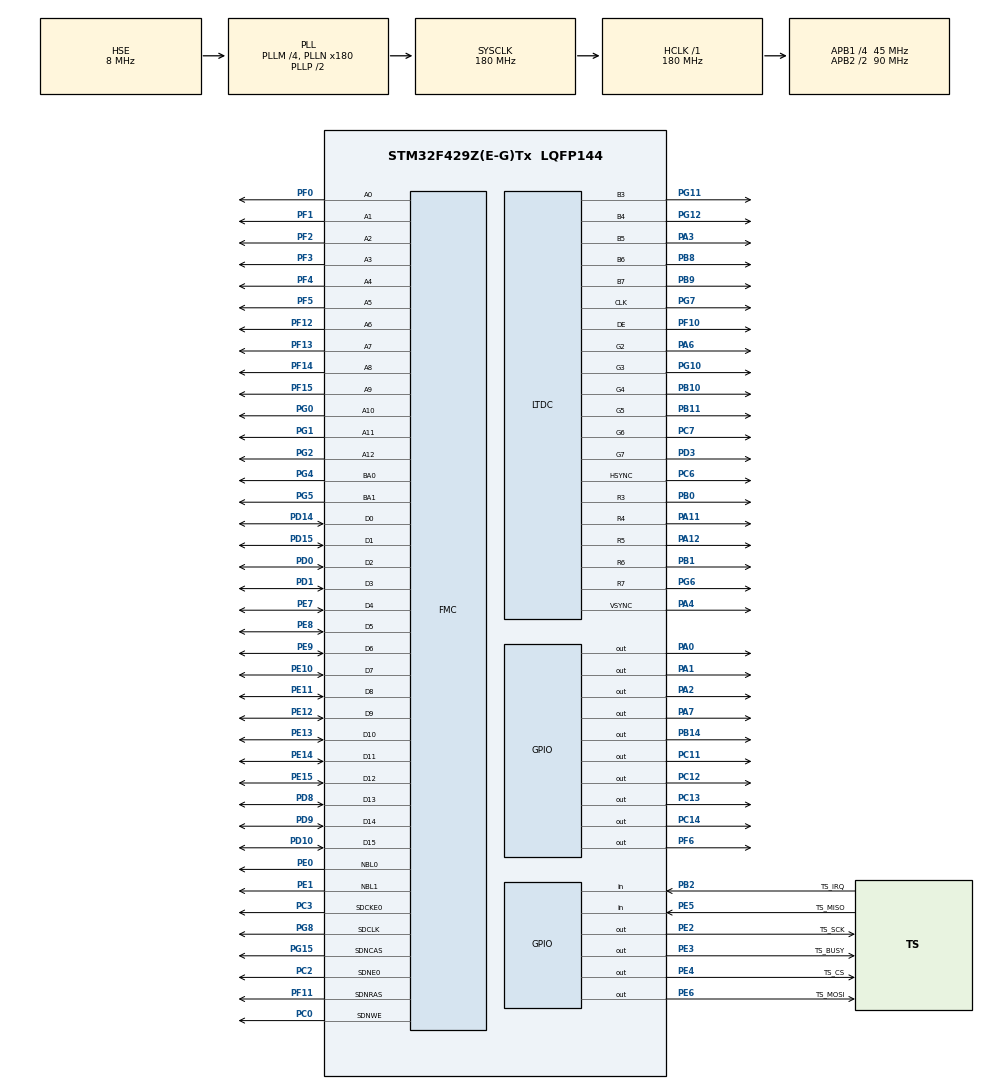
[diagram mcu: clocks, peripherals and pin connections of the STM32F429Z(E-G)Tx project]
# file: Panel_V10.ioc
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DMA2D.ColorMode=DMA2D_OUTPUT_RGB565
FMC.CASLatency1=FMC_SDRAM_CAS_LATENCY_2
FMC.ColumnBitsNumber1=FMC_SDRAM_COLUMN_BITS_NUM_9
FMC.ExitSelfRefreshDelay1=7
FMC.LoadToActiveDelay1=2
FMC.RCDDelay1=2
FMC.RPDelay1=2
FMC.RPDelay2=2
FMC.RowCycleDelay1=7
FMC.RowCycleDelay2=7
FMC.SDClockPeriod1=FMC_SDRAM_CLOCK_PERIOD_2
FMC.SDClockPeriod2=FMC_SDRAM_CLOCK_PERIOD_2
FMC.SelfRefreshTime1=4
FMC.WriteRecoveryTime1=3
FREERTOS.Tasks01=defaultTask,0,2048,StartDefaultTask,Default,NULL,Dynamic,NULL,NULL
FREERTOS.configMINIMAL_STACK_SIZE=2048
LTDC.ActiveH=272
LTDC.ActiveW=480
LTDC.Alpha_L0=255
LTDC.FBStartAdress_L0=0xC0000000
LTDC.HBP=43
LTDC.HFP=2
LTDC.HSync=1
LTDC.ImageHeight_L0=272
LTDC.ImageWidth_L0=480
LTDC.Layers=0
LTDC.PixelFormat_L0=LTDC_PIXEL_FORMAT_RGB565
LTDC.VBP=12
LTDC.VFP=2
LTDC.VSync=1
LTDC.WindowX1_L0=480
LTDC.WindowY1_L0=272
Mcu.Family=STM32F4
Mcu.Name=STM32F429Z(E-G)Tx
Mcu.Package=LQFP144
NVIC.DMA2D_IRQn=true\:5\:0\:false\:false\:true\:true\:true\:true
NVIC.LTDC_IRQn=true\:5\:0\:false\:false\:true\:true\:true\:true
NVIC.PriorityGroup=NVIC_PRIORITYGROUP_4
NVIC.RCC_IRQn=true\:5\:0\:false\:false\:true\:true\:false\:false
NVIC.TIM1_UP_TIM10_IRQn=true\:0\:0\:false\:false\:true\:false\:true\:true
NVIC.TimeBase=TIM1_UP_TIM10_IRQn
NVIC.TimeBaseIP=TIM1
PA0/WKUP.Signal=GPIO_Output
PA1.Signal=GPIO_Output
PA11.GPIO_Speed=GPIO_SPEED_FREQ_VERY_HIGH
PA11.Mode=RGB565
PA11.Signal=LTDC_R4
PA12.GPIO_Speed=GPIO_SPEED_FREQ_VERY_HIGH
PA12.Mode=RGB565
PA12.Signal=LTDC_R5
PA13.Mode=Serial_Wire
PA13.Signal=SYS_JTMS-SWDIO
PA14.Mode=Serial_Wire
PA14.Signal=SYS_JTCK-SWCLK
PA2.Signal=GPIO_Output
PA3.GPIO_Speed=GPIO_SPEED_FREQ_VERY_HIGH
PA3.Mode=RGB565
PA3.Signal=LTDC_B5
PA4.GPIO_Speed=GPIO_SPEED_FREQ_VERY_HIGH
PA4.Mode=RGB565
PA4.Signal=LTDC_VSYNC
PA6.GPIO_Speed=GPIO_SPEED_FREQ_VERY_HIGH
PA6.Mode=RGB565
PA6.Signal=LTDC_G2
PA7.Signal=GPIO_Output
PB0.GPIO_Speed=GPIO_SPEED_FREQ_VERY_HIGH
PB0.Mode=RGB565
PB0.Signal=LTDC_R3
PB1.GPIO_Speed=GPIO_SPEED_FREQ_VERY_HIGH
PB1.Mode=RGB565
PB1.Signal=LTDC_R6
PB10.GPIO_Speed=GPIO_SPEED_FREQ_VERY_HIGH
PB10.Mode=RGB565
PB10.Signal=LTDC_G4
PB11.GPIO_Speed=GPIO_SPEED_FREQ_VERY_HIGH
PB11.Mode=RGB565
PB11.Signal=LTDC_G5
PB14.PinState=GPIO_PIN_SET
PB14.Signal=GPIO_Output
PB2/BOOT1.GPIO_Label=TS_IRQ
PB2/BOOT1.Signal=GPIO_Input
PB8.GPIO_Speed=GPIO_SPEED_FREQ_VERY_HIGH
PB8.Mode=RGB565
PB8.Signal=LTDC_B6
PB9.GPIO_Speed=GPIO_SPEED_FREQ_VERY_HIGH
PB9.Mode=RGB565
PB9.Signal=LTDC_B7
PC0.Signal=FMC_SDNWE
PC11.Signal=GPIO_Output
PC12.Signal=GPIO_Output
PC13.Signal=GPIO_Output
PC14/OSC32_IN.Signal=GPIO_Output
PC2.Mode=SdramChipSelect1_1
PC2.Signal=FMC_SDNE0
PC3.Mode=SdramChipSelect1_1
PC3.Signal=FMC_SDCKE0
PC6.GPIO_Speed=GPIO_SPEED_FREQ_VERY_HIGH
PC6.Mode=RGB565
PC6.Signal=LTDC_HSYNC
PC7.GPIO_Speed=GPIO_SPEED_FREQ_VERY_HIGH
PC7.Mode=RGB565
PC7.Signal=LTDC_G6
PD0.Signal=FMC_D2_DA2
PD1.Signal=FMC_D3_DA3
PD10.Signal=FMC_D15_DA15
PD14.Signal=FMC_D0_DA0
PD15.Signal=FMC_D1_DA1
PD3.GPIO_Speed=GPIO_SPEED_FREQ_VERY_HIGH
PD3.Mode=RGB565
PD3.Signal=LTDC_G7
PD8.Signal=FMC_D13_DA13
PD9.Signal=FMC_D14_DA14
PE0.Signal=FMC_NBL0
PE1.Signal=FMC_NBL1
PE10.Signal=FMC_D7_DA7
PE11.Signal=FMC_D8_DA8
PE12.Signal=FMC_D9_DA9
PE13.Signal=FMC_D10_DA10
PE14.Signal=FMC_D11_DA11
PE15.Signal=FMC_D12_DA12
PE2.GPIO_Label=TS_SCK
PE2.Signal=GPIO_Output
PE3.GPIO_Label=TS_BUSY
PE3.Signal=GPIO_Output
PE4.GPIO_Label=TS_CS
PE4.Signal=GPIO_Output
PE5.GPIO_Label=TS_MISO
PE5.Signal=GPIO_Input
PE6.GPIO_Label=TS_MOSI
PE6.Signal=GPIO_Output
PE7.Signal=FMC_D4_DA4
PE8.Signal=FMC_D5_DA5
PE9.Signal=FMC_D6_DA6
PF0.Signal=FMC_A0
PF1.Signal=FMC_A1
PF10.GPIO_Speed=GPIO_SPEED_FREQ_VERY_HIGH
PF10.Mode=RGB565
PF10.Signal=LTDC_DE
PF11.Signal=FMC_SDNRAS
PF12.Signal=FMC_A6
PF13.Signal=FMC_A7
PF14.Signal=FMC_A8
PF15.Signal=FMC_A9
PF2.Signal=FMC_A2
PF3.Signal=FMC_A3
PF4.Signal=FMC_A4
PF5.Signal=FMC_A5
PF6.PinState=GPIO_PIN_SET
PF6.Signal=GPIO_Output
PG0.Signal=FMC_A10
PG1.Signal=FMC_A11
PG10.GPIO_Speed=GPIO_SPEED_FREQ_VERY_HIGH
PG10.Mode=RGB565
PG10.Signal=LTDC_G3
PG11.GPIO_Speed=GPIO_SPEED_FREQ_VERY_HIGH
PG11.Mode=RGB565
PG11.Signal=LTDC_B3
PG12.GPIO_Speed=GPIO_SPEED_FREQ_VERY_HIGH
PG12.Mode=RGB565
PG12.Signal=LTDC_B4
PG15.Signal=FMC_SDNCAS
PG2.Signal=FMC_A12
PG4.Signal=FMC_A14_BA0
PG5.Signal=FMC_A15_BA1
PG6.GPIO_Speed=GPIO_SPEED_FREQ_VERY_HIGH
PG6.Mode=RGB565
PG6.Signal=LTDC_R7
PG7.GPIO_Speed=GPIO_SPEED_FREQ_VERY_HIGH
PG7.Mode=RGB565
PG7.Signal=LTDC_CLK
PG8.Signal=FMC_SDCLK
PH0/OSC_IN.Mode=HSE-External-Oscillator
PH0/OSC_IN.Signal=RCC_OSC_IN
PH1/OSC_OUT.Mode=HSE-External-Oscillator
PH1/OSC_OUT.Signal=RCC_OSC_OUT
ProjectManager.HeapSize=0x200
ProjectManager.StackSize=0x400
ProjectManager.TargetToolchain=STM32CubeIDE
RCC.48MHZClocksFreq_Value=90000000
RCC.AHBFreq_Value=180000000
RCC.APB1CLKDivider=RCC_HCLK_DIV4
RCC.APB1Freq_Value=45000000
RCC.APB1TimFreq_Value=90000000
RCC.APB2CLKDivider=RCC_HCLK_DIV2
RCC.APB2Freq_Value=90000000
RCC.APB2TimFreq_Value=180000000
RCC.CortexFreq_Value=180000000
RCC.HCLKFreq_Value=180000000
RCC.HSE_VALUE=8000000
RCC.HSI_VALUE=16000000
RCC.LSE_VALUE=32768
RCC.PLLM=4
RCC.PLLN=180
RCC.PLLSAIDivR=RCC_PLLSAIDIVR_4
RCC.PLLSAIN=54
RCC.PLLSAIR=3
RCC.PLLSourceVirtual=RCC_PLLSOURCE_HSE
RCC.PWR_Regulator_Voltage_Scale=PWR_REGULATOR_VOLTAGE_SCALE1
RCC.SYSCLKFreq_VALUE=180000000
RCC.SYSCLKSource=RCC_SYSCLKSOURCE_PLLCLK
RCC.VCOOutputFreq_Value=360000000
SH.FMC_A0.0=FMC_A0,13b-sda1
SH.FMC_A1.0=FMC_A1,13b-sda1
SH.FMC_A10.0=FMC_A10,13b-sda1
SH.FMC_A11.0=FMC_A11,13b-sda1
SH.FMC_A12.0=FMC_A12,13b-sda1
SH.FMC_A14_BA0.0=FMC_BA0,FourSdramBanks1
SH.FMC_A15_BA1.0=FMC_BA1,FourSdramBanks1
SH.FMC_A2.0=FMC_A2,13b-sda1
SH.FMC_A3.0=FMC_A3,13b-sda1
SH.FMC_A4.0=FMC_A4,13b-sda1
SH.FMC_A5.0=FMC_A5,13b-sda1
SH.FMC_A6.0=FMC_A6,13b-sda1
SH.FMC_A7.0=FMC_A7,13b-sda1
SH.FMC_A8.0=FMC_A8,13b-sda1
SH.FMC_A9.0=FMC_A9,13b-sda1
SH.FMC_D0_DA0.0=FMC_D0,sd-16b-d1
SH.FMC_D10_DA10.0=FMC_D10,sd-16b-d1
SH.FMC_D11_DA11.0=FMC_D11,sd-16b-d1
SH.FMC_D12_DA12.0=FMC_D12,sd-16b-d1
SH.FMC_D13_DA13.0=FMC_D13,sd-16b-d1
SH.FMC_D14_DA14.0=FMC_D14,sd-16b-d1
SH.FMC_D15_DA15.0=FMC_D15,sd-16b-d1
SH.FMC_D1_DA1.0=FMC_D1,sd-16b-d1
SH.FMC_D2_DA2.0=FMC_D2,sd-16b-d1
SH.FMC_D3_DA3.0=FMC_D3,sd-16b-d1
SH.FMC_D4_DA4.0=FMC_D4,sd-16b-d1
SH.FMC_D5_DA5.0=FMC_D5,sd-16b-d1
SH.FMC_D6_DA6.0=FMC_D6,sd-16b-d1
SH.FMC_D7_DA7.0=FMC_D7,sd-16b-d1
SH.FMC_D8_DA8.0=FMC_D8,sd-16b-d1
SH.FMC_D9_DA9.0=FMC_D9,sd-16b-d1
SH.FMC_NBL0.0=FMC_NBL0,Sd2ByteEnable1
SH.FMC_NBL1.0=FMC_NBL1,Sd2ByteEnable1
SH.FMC_SDCLK.0=FMC_SDCLK,13b-sda1
SH.FMC_SDNCAS.0=FMC_SDNCAS,13b-sda1
SH.FMC_SDNRAS.0=FMC_SDNRAS,13b-sda1
SH.FMC_SDNWE.0=FMC_SDNWE,13b-sda1
STMicroelectronics.X-CUBE-TOUCHGFX.4.16.1.ApplicationCcGraphicsJjApplication=TouchGFXOoGenerator
STMicroelectronics.X-CUBE-TOUCHGFX.4.16.1.tgfx_address1=0xC0000000
STMicroelectronics.X-CUBE-TOUCHGFX.4.16.1.tgfx_display_interface=disp_ltdc
STMicroelectronics.X-CUBE-TOUCHGFX.4.16.1.tgfx_hardware_accelerator=dma_2d
STMicroelectronics.X-CUBE-TOUCHGFX.4.16.1.tgfx_location=By Address
STMicroelectronics.X-CUBE-TOUCHGFX.4.16.1.tgfx_vsync=vsync_ltdc
VP_CRC_VS_CRC.Mode=CRC_Activate
VP_DMA2D_VS_DMA2D.Mode=DMA2D_Activate
VP_FREERTOS_VS_CMSIS_V1.Mode=CMSIS_V1
VP_STMicroelectronics.X-CUBE-TOUCHGFX_VS_GraphicsJjApplication_4.16.1.Mode=GraphicsJjApplication
VP_SYS_VS_tim1.Mode=TIM1
board=custom

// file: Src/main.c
/* USER CODE BEGIN Header */
/**
  ******************************************************************************
  * @file           : main.c
  * @brief          : Main program body
  ******************************************************************************
  * @attention
  *
  * <h2><center>&copy; Copyright (c) 2020 STMicroelectronics.
  * All rights reserved.</center></h2>
  *
  * This software component is licensed by ST under BSD 3-Clause license,
  * the "License"; You may not use this file except in compliance with the
  * License. You may obtain a copy of the License at:
  *                        opensource.org/licenses/BSD-3-Clause
  *
  ******************************************************************************
  */
/* USER CODE END Header */
#include "main.h"
#include "cmsis_os.h"
#include "app_touchgfx.h"

/* USER CODE BEGIN Includes */
int tickcounter;
int q;
int tick;
int m;

/* USER CODE END Includes */

/* USER CODE BEGIN PM */
# define WRITE_READ_ADDR                                ((uint16_t*)0xC0000000)

# define SDRAM_MODEREG_BURST_LENGTH_1                   ((uint16_t)0x0000)
# define SDRAM_MODEREG_BURST_LENGTH_2                   ((uint16_t)0x0001)
# define SDRAM_MODEREG_BURST_LENGTH_4                   ((uint16_t)0x0002)
# define SDRAM_MODEREG_BURST_LENGTH_8                   ((uint16_t)0x0004)
# define SDRAM_MODEREG_BURST_TYPE_SEQUENTIAL            ((uint16_t)0x0000)
# define SDRAM_MODEREG_BURST_TYPE_INTERLEAVED           ((uint16_t)0x0008)
# define SDRAM_MODEREG_CAS_LATENCY_2                    ((uint16_t)0x0020)
# define SDRAM_MODEREG_CAS_LATENCY_3                    ((uint16_t)0x0030)
# define SDRAM_MODEREG_OPERATING_MODE_STANDARD          ((uint16_t)0x0000)
# define SDRAM_MODEREG_WRITEBURST_MODE_PROGRAMMED       ((uint16_t)0x0000)
# define SDRAM_MODEREG_WRITEBURST_MODE_SINGLE           ((uint16_t)0x0200)

# define REFRESH_COUNT                                  ((uint32_t)1835)        // SDRAM Refresh Counter (90MHz SD Clock)

void SDRAM_Initialization_Sequence(SDRAM_HandleTypeDef *hsdram, FMC_SDRAM_CommandTypeDef *Command)
{
  __IO uint32_t tmpmrd = 0;

  // Step 3: Configure a clock configuration enable command
  Command->CommandMode                  =       FMC_SDRAM_CMD_CLK_ENABLE;
  Command->CommandTarget                =       FMC_SDRAM_CMD_TARGET_BANK1;
  Command->AutoRefreshNumber            =       1;
  Command->ModeRegisterDefinition       =       0;

  // Send the command
  HAL_SDRAM_SendCommand(hsdram, Command, 0x1000);

  // Step 4: Insert 100 ms delay
  HAL_Delay(100);

  // Step 5: Configure a PALL (Precharge All) command
  Command->CommandMode                  =       FMC_SDRAM_CMD_PALL;
  Command->CommandTarget                =       FMC_SDRAM_CMD_TARGET_BANK1;
  Command->AutoRefreshNumber            =       1;
  Command->ModeRegisterDefinition       =       0;

  // Send the command
  HAL_SDRAM_SendCommand(hsdram, Command, 0x1000);

  // Step 6: Configure a Auto-Refresh command
  Command->CommandMode                  =       FMC_SDRAM_CMD_AUTOREFRESH_MODE;
  Command->CommandTarget                =       FMC_SDRAM_CMD_TARGET_BANK1;
  Command->AutoRefreshNumber            =       8;
  Command->ModeRegisterDefinition       =       0;

  // Send the command
  HAL_SDRAM_SendCommand(hsdram, Command, 0x1000);

  // Step 7: Program the external memory mode register
  tmpmrd = (uint32_t) SDRAM_MODEREG_BURST_LENGTH_2              |
                      SDRAM_MODEREG_BURST_TYPE_SEQUENTIAL       |
                      SDRAM_MODEREG_CAS_LATENCY_3               |
                      SDRAM_MODEREG_OPERATING_MODE_STANDARD     |
                      SDRAM_MODEREG_WRITEBURST_MODE_SINGLE      ;

  Command->CommandMode                  =       FMC_SDRAM_CMD_LOAD_MODE;
  Command->CommandTarget                =       FMC_SDRAM_CMD_TARGET_BANK1;
  Command->AutoRefreshNumber            =       1;
  Command->ModeRegisterDefinition       =       0x0220;

  // Send the command
  HAL_SDRAM_SendCommand(hsdram, Command, 0x1000);

  // Step 8: Set the refresh rate counter -----> (15.62 us * Freq) - 20
  // Set the device refresh counter
  HAL_SDRAM_ProgramRefreshRate(hsdram, REFRESH_COUNT);
}

/* USER CODE END PM */

CRC_HandleTypeDef hcrc;

DMA2D_HandleTypeDef hdma2d;

LTDC_HandleTypeDef hltdc;

SDRAM_HandleTypeDef hsdram1;

osThreadId defaultTaskHandle;

void SystemClock_Config(void);
static void MX_GPIO_Init(void);
static void MX_CRC_Init(void);
static void MX_FMC_Init(void);
static void MX_LTDC_Init(void);
static void MX_DMA2D_Init(void);
void StartDefaultTask(void const * argument);

/* USER CODE BEGIN PFP */
void StartTask1(void const * argument);
void StartTask2(void const * argument);

/* USER CODE END PFP */

int main(void)
{

  /* MCU Configuration--------------------------------------------------------*/

  /* Reset of all peripherals, Initializes the Flash interface and the Systick. */
  HAL_Init();

  /* Configure the system clock */
  SystemClock_Config();

  /* Initialize all configured peripherals */
  MX_GPIO_Init();
  MX_CRC_Init();
  MX_FMC_Init();
  MX_LTDC_Init();
  MX_DMA2D_Init();
  MX_TouchGFX_Init();
  /* USER CODE BEGIN 2 */
  HAL_GPIO_WritePin(GPIOA, GPIO_PIN_0, GPIO_PIN_SET);
  HAL_GPIO_WritePin(GPIOA, GPIO_PIN_1, GPIO_PIN_SET);
  HAL_GPIO_WritePin(GPIOA, GPIO_PIN_2, GPIO_PIN_SET);
  HAL_GPIO_WritePin(GPIOA, GPIO_PIN_7, GPIO_PIN_SET);
  HAL_GPIO_WritePin(GPIOC, GPIO_PIN_11, GPIO_PIN_SET);
  HAL_GPIO_WritePin(GPIOC, GPIO_PIN_12, GPIO_PIN_SET);
  HAL_GPIO_WritePin(GPIOC, GPIO_PIN_13, GPIO_PIN_SET);
  HAL_GPIO_WritePin(GPIOC, GPIO_PIN_14, GPIO_PIN_SET);
  /* USER CODE END 2 */

  /* Create the thread(s) */
  /* definition and creation of defaultTask */
  osThreadDef(defaultTask, StartDefaultTask, osPriorityNormal, 0, 2048);
  defaultTaskHandle = osThreadCreate(osThread(defaultTask), NULL);

  /* USER CODE BEGIN RTOS_THREADS */
  /* add threads, ... */
  osThreadDef(Task1, StartTask1, osPriorityNormal, 0, 128);
  defaultTaskHandle = osThreadCreate(osThread(Task1), NULL);

  osThreadDef(Task2, StartTask2, osPriorityNormal, 0, 128);
  defaultTaskHandle = osThreadCreate(osThread(Task2), NULL);

  /* USER CODE END RTOS_THREADS */

  /* Start scheduler */
  osKernelStart();

  /* We should never get here as control is now taken by the scheduler */
  /* Infinite loop */
  while (1)
  {

  }
}

void SystemClock_Config(void)
{
  RCC_OscInitTypeDef RCC_OscInitStruct = {0};
  RCC_ClkInitTypeDef RCC_ClkInitStruct = {0};

  /** Configure the main internal regulator output voltage
  */
  __HAL_RCC_PWR_CLK_ENABLE();
  __HAL_PWR_VOLTAGESCALING_CONFIG(PWR_REGULATOR_VOLTAGE_SCALE1);
  /** Initializes the RCC Oscillators according to the specified parameters
  * in the RCC_OscInitTypeDef structure.
  */
  RCC_OscInitStruct.OscillatorType = RCC_OSCILLATORTYPE_HSE;
  RCC_OscInitStruct.HSEState = RCC_HSE_ON;
  RCC_OscInitStruct.PLL.PLLState = RCC_PLL_ON;
  RCC_OscInitStruct.PLL.PLLSource = RCC_PLLSOURCE_HSE;
  RCC_OscInitStruct.PLL.PLLM = 4;
  RCC_OscInitStruct.PLL.PLLN = 180;
  RCC_OscInitStruct.PLL.PLLP = RCC_PLLP_DIV2;
  RCC_OscInitStruct.PLL.PLLQ = 4;
  if (HAL_RCC_OscConfig(&RCC_OscInitStruct) != HAL_OK)
  {
    Error_Handler();
  }
  /** Activate the Over-Drive mode
  */
  if (HAL_PWREx_EnableOverDrive() != HAL_OK)
  {
    Error_Handler();
  }
  /** Initializes the CPU, AHB and APB buses clocks
  */
  RCC_ClkInitStruct.ClockType = RCC_CLOCKTYPE_HCLK|RCC_CLOCKTYPE_SYSCLK
                              |RCC_CLOCKTYPE_PCLK1|RCC_CLOCKTYPE_PCLK2;
  RCC_ClkInitStruct.SYSCLKSource = RCC_SYSCLKSOURCE_PLLCLK;
  RCC_ClkInitStruct.AHBCLKDivider = RCC_SYSCLK_DIV1;
  RCC_ClkInitStruct.APB1CLKDivider = RCC_HCLK_DIV4;
  RCC_ClkInitStruct.APB2CLKDivider = RCC_HCLK_DIV2;

  if (HAL_RCC_ClockConfig(&RCC_ClkInitStruct, FLASH_LATENCY_5) != HAL_OK)
  {
    Error_Handler();
  }
}

static void MX_CRC_Init(void)
{

  hcrc.Instance = CRC;
  if (HAL_CRC_Init(&hcrc) != HAL_OK)
  {
    Error_Handler();
  }

}

static void MX_DMA2D_Init(void)
{

  hdma2d.Instance = DMA2D;
  hdma2d.Init.Mode = DMA2D_M2M;
  hdma2d.Init.ColorMode = DMA2D_OUTPUT_RGB565;
  hdma2d.Init.OutputOffset = 0;
  hdma2d.LayerCfg[1].InputOffset = 0;
  hdma2d.LayerCfg[1].InputColorMode = DMA2D_INPUT_RGB565;
  hdma2d.LayerCfg[1].AlphaMode = DMA2D_NO_MODIF_ALPHA;
  hdma2d.LayerCfg[1].InputAlpha = 0;
  if (HAL_DMA2D_Init(&hdma2d) != HAL_OK)
  {
    Error_Handler();
  }
  if (HAL_DMA2D_ConfigLayer(&hdma2d, 1) != HAL_OK)
  {
    Error_Handler();
  }

}

static void MX_LTDC_Init(void)
{

  LTDC_LayerCfgTypeDef pLayerCfg = {0};

  hltdc.Instance = LTDC;
  hltdc.Init.HSPolarity = LTDC_HSPOLARITY_AL;
  hltdc.Init.VSPolarity = LTDC_VSPOLARITY_AL;
  hltdc.Init.DEPolarity = LTDC_DEPOLARITY_AL;
  hltdc.Init.PCPolarity = LTDC_PCPOLARITY_IPC;
  hltdc.Init.HorizontalSync = 0;
  hltdc.Init.VerticalSync = 0;
  hltdc.Init.AccumulatedHBP = 43;
  hltdc.Init.AccumulatedVBP = 12;
  hltdc.Init.AccumulatedActiveW = 523;
  hltdc.Init.AccumulatedActiveH = 284;
  hltdc.Init.TotalWidth = 525;
  hltdc.Init.TotalHeigh = 286;
  hltdc.Init.Backcolor.Blue = 0;
  hltdc.Init.Backcolor.Green = 0;
  hltdc.Init.Backcolor.Red = 0;
  if (HAL_LTDC_Init(&hltdc) != HAL_OK)
  {
    Error_Handler();
  }
  pLayerCfg.WindowX0 = 0;
  pLayerCfg.WindowX1 = 480;
  pLayerCfg.WindowY0 = 0;
  pLayerCfg.WindowY1 = 272;
  pLayerCfg.PixelFormat = LTDC_PIXEL_FORMAT_RGB565;
  pLayerCfg.Alpha = 255;
  pLayerCfg.Alpha0 = 0;
  pLayerCfg.BlendingFactor1 = LTDC_BLENDING_FACTOR1_CA;
  pLayerCfg.BlendingFactor2 = LTDC_BLENDING_FACTOR2_CA;
  pLayerCfg.FBStartAdress = 0xC0000000;
  pLayerCfg.ImageWidth = 480;
  pLayerCfg.ImageHeight = 272;
  pLayerCfg.Backcolor.Blue = 0;
  pLayerCfg.Backcolor.Green = 0;
  pLayerCfg.Backcolor.Red = 0;
  if (HAL_LTDC_ConfigLayer(&hltdc, &pLayerCfg, 0) != HAL_OK)
  {
    Error_Handler();
  }

}

/* FMC initialization function */
static void MX_FMC_Init(void)
{

  FMC_SDRAM_TimingTypeDef SdramTiming = {0};

  /** Perform the SDRAM1 memory initialization sequence
  */
  hsdram1.Instance = FMC_SDRAM_DEVICE;
  /* hsdram1.Init */
  hsdram1.Init.SDBank = FMC_SDRAM_BANK1;
  hsdram1.Init.ColumnBitsNumber = FMC_SDRAM_COLUMN_BITS_NUM_9;
  hsdram1.Init.RowBitsNumber = FMC_SDRAM_ROW_BITS_NUM_13;
  hsdram1.Init.MemoryDataWidth = FMC_SDRAM_MEM_BUS_WIDTH_16;
  hsdram1.Init.InternalBankNumber = FMC_SDRAM_INTERN_BANKS_NUM_4;
  hsdram1.Init.CASLatency = FMC_SDRAM_CAS_LATENCY_2;
  hsdram1.Init.WriteProtection = FMC_SDRAM_WRITE_PROTECTION_DISABLE;
  hsdram1.Init.SDClockPeriod = FMC_SDRAM_CLOCK_PERIOD_2;
  hsdram1.Init.ReadBurst = FMC_SDRAM_RBURST_DISABLE;
  hsdram1.Init.ReadPipeDelay = FMC_SDRAM_RPIPE_DELAY_0;
  /* SdramTiming */
  SdramTiming.LoadToActiveDelay = 2;
  SdramTiming.ExitSelfRefreshDelay = 7;
  SdramTiming.SelfRefreshTime = 4;
  SdramTiming.RowCycleDelay = 7;
  SdramTiming.WriteRecoveryTime = 3;
  SdramTiming.RPDelay = 2;
  SdramTiming.RCDDelay = 2;

  if (HAL_SDRAM_Init(&hsdram1, &SdramTiming) != HAL_OK)
  {
    Error_Handler( );
  }

  /* USER CODE BEGIN FMC_Init 2 */
  FMC_SDRAM_CommandTypeDef      SDRAM_Command;
  SDRAM_Initialization_Sequence(&hsdram1, &SDRAM_Command);

  /* USER CODE END FMC_Init 2 */
}

static void MX_GPIO_Init(void)
{
  GPIO_InitTypeDef GPIO_InitStruct = {0};

  /* GPIO Ports Clock Enable */
  __HAL_RCC_GPIOE_CLK_ENABLE();
  __HAL_RCC_GPIOC_CLK_ENABLE();
  __HAL_RCC_GPIOF_CLK_ENABLE();
  __HAL_RCC_GPIOH_CLK_ENABLE();
  __HAL_RCC_GPIOA_CLK_ENABLE();
  __HAL_RCC_GPIOB_CLK_ENABLE();
  __HAL_RCC_GPIOG_CLK_ENABLE();
  __HAL_RCC_GPIOD_CLK_ENABLE();

  /*Configure GPIO pin Output Level */
  HAL_GPIO_WritePin(GPIOE, TS_SCK_Pin|TS_BUSY_Pin|TS_CS_Pin|TS_MOSI_Pin, GPIO_PIN_RESET);

  /*Configure GPIO pin Output Level */
  HAL_GPIO_WritePin(GPIOC, GPIO_PIN_13|GPIO_PIN_14|GPIO_PIN_11|GPIO_PIN_12, GPIO_PIN_RESET);

  /*Configure GPIO pin Output Level */
  HAL_GPIO_WritePin(GPIOF, GPIO_PIN_6, GPIO_PIN_SET);

  /*Configure GPIO pin Output Level */
  HAL_GPIO_WritePin(GPIOA, GPIO_PIN_0|GPIO_PIN_1|GPIO_PIN_2|GPIO_PIN_7, GPIO_PIN_RESET);

  /*Configure GPIO pin Output Level */
  HAL_GPIO_WritePin(GPIOB, GPIO_PIN_14, GPIO_PIN_SET);

  /*Configure GPIO pins : TS_SCK_Pin TS_BUSY_Pin TS_CS_Pin TS_MOSI_Pin */
  GPIO_InitStruct.Pin = TS_SCK_Pin|TS_BUSY_Pin|TS_CS_Pin|TS_MOSI_Pin;
  GPIO_InitStruct.Mode = GPIO_MODE_OUTPUT_PP;
  GPIO_InitStruct.Pull = GPIO_NOPULL;
  GPIO_InitStruct.Speed = GPIO_SPEED_FREQ_LOW;
  HAL_GPIO_Init(GPIOE, &GPIO_InitStruct);

  /*Configure GPIO pin : TS_MISO_Pin */
  GPIO_InitStruct.Pin = TS_MISO_Pin;
  GPIO_InitStruct.Mode = GPIO_MODE_INPUT;
  GPIO_InitStruct.Pull = GPIO_NOPULL;
  HAL_GPIO_Init(TS_MISO_GPIO_Port, &GPIO_InitStruct);

  /*Configure GPIO pins : PC13 PC14 PC11 PC12 */
  GPIO_InitStruct.Pin = GPIO_PIN_13|GPIO_PIN_14|GPIO_PIN_11|GPIO_PIN_12;
  GPIO_InitStruct.Mode = GPIO_MODE_OUTPUT_PP;
  GPIO_InitStruct.Pull = GPIO_NOPULL;
  GPIO_InitStruct.Speed = GPIO_SPEED_FREQ_LOW;
  HAL_GPIO_Init(GPIOC, &GPIO_InitStruct);

  /*Configure GPIO pin : PF6 */
  GPIO_InitStruct.Pin = GPIO_PIN_6;
  GPIO_InitStruct.Mode = GPIO_MODE_OUTPUT_PP;
  GPIO_InitStruct.Pull = GPIO_NOPULL;
  GPIO_InitStruct.Speed = GPIO_SPEED_FREQ_LOW;
  HAL_GPIO_Init(GPIOF, &GPIO_InitStruct);

  /*Configure GPIO pins : PA0 PA1 PA2 PA7 */
  GPIO_InitStruct.Pin = GPIO_PIN_0|GPIO_PIN_1|GPIO_PIN_2|GPIO_PIN_7;
  GPIO_InitStruct.Mode = GPIO_MODE_OUTPUT_PP;
  GPIO_InitStruct.Pull = GPIO_NOPULL;
  GPIO_InitStruct.Speed = GPIO_SPEED_FREQ_LOW;
  HAL_GPIO_Init(GPIOA, &GPIO_InitStruct);

  /*Configure GPIO pin : TS_IRQ_Pin */
  GPIO_InitStruct.Pin = TS_IRQ_Pin;
  GPIO_InitStruct.Mode = GPIO_MODE_INPUT;
  GPIO_InitStruct.Pull = GPIO_NOPULL;
  HAL_GPIO_Init(TS_IRQ_GPIO_Port, &GPIO_InitStruct);

  /*Configure GPIO pin : PB14 */
  GPIO_InitStruct.Pin = GPIO_PIN_14;
  GPIO_InitStruct.Mode = GPIO_MODE_OUTPUT_PP;
  GPIO_InitStruct.Pull = GPIO_NOPULL;
  GPIO_InitStruct.Speed = GPIO_SPEED_FREQ_LOW;
  HAL_GPIO_Init(GPIOB, &GPIO_InitStruct);

}

/* USER CODE BEGIN 4 */
void StartTask1(void const * argument)
{
  /* Infinite loop */

  for(;;)
  {
    //HAL_GPIO_TogglePin(GPIOA, GPIO_PIN_0);
    osDelay(1000);
  if (tickcounter<90)
  {
    tickcounter++;
  }
  else
  {
    tickcounter=0;
  };
  }
}

void StartTask2(void const * argument)
{
  /* Infinite loop */
  for(;;)
  {
    //HAL_GPIO_TogglePin(GPIOA, GPIO_PIN_1);
    osDelay(500);
    if (m<100)
      m++;
    else
      m=0;

  }
}
/* USER CODE END 4 */

void StartDefaultTask(void const * argument)
{
  /* USER CODE BEGIN 5 */
  MX_TouchGFX_Process();

  /* Infinite loop */
  for(;;)
  {
    osDelay(1);
  }
  /* USER CODE END 5 */
}

void HAL_TIM_PeriodElapsedCallback(TIM_HandleTypeDef *htim)
{
  if (htim->Instance == TIM1) {
    HAL_IncTick();
  }
}

void Error_Handler(void)
{
  __disable_irq();
  while (1)
  {
  }
}

/************************ (C) COPYRIGHT STMicroelectronics *****END OF FILE****/
